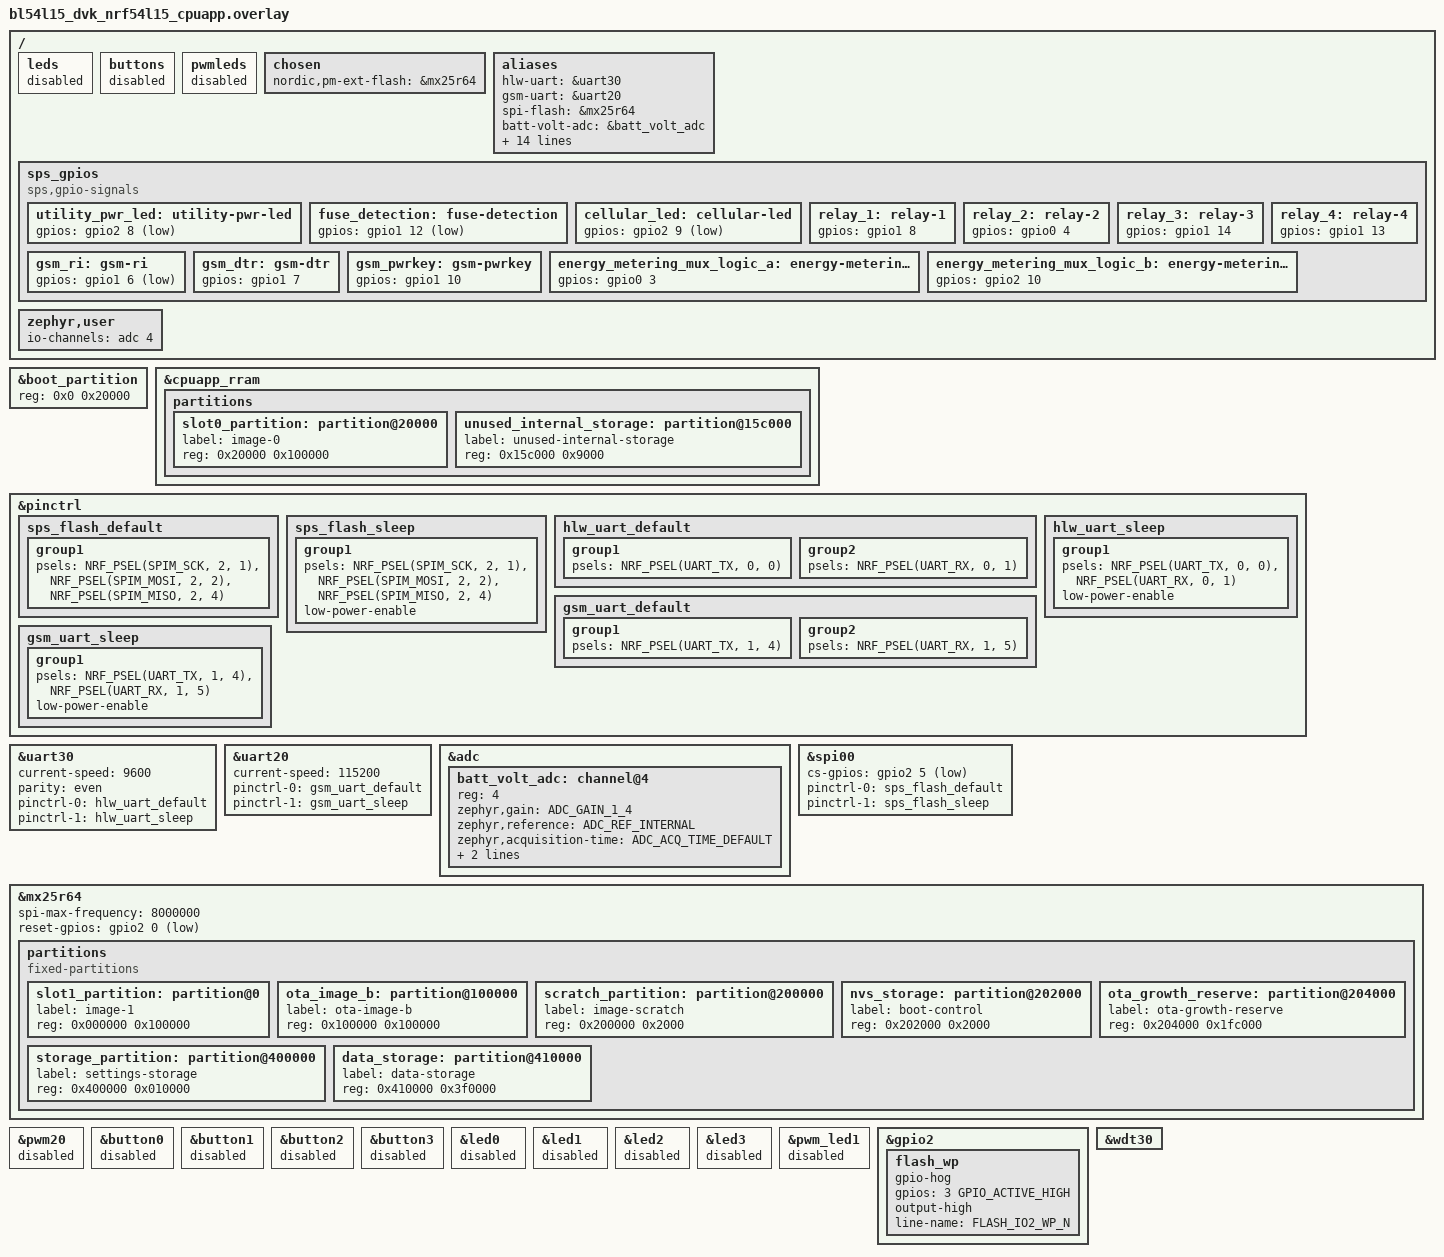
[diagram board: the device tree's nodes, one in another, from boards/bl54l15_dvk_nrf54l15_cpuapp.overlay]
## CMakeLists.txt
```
# SPDX-License-Identifier: Apache-2.0

cmake_minimum_required(VERSION 3.20.0)

find_package(Zephyr REQUIRED HINTS $ENV{ZEPHYR_BASE})
project(smart_power_socket)

target_sources(app PRIVATE
	src/main.cpp
	src/alerts.cpp
	src/sms_commands.cpp
	src/device_status.cpp
	src/app_config.cpp
	src/hardware/gpio_con.cpp
	src/hardware/uart_con.cpp
	src/hardware/adc_con.cpp
	src/sensors/hlw811x.cpp
	src/sensors/externalLibs/hlw811x/hlw811x.c
	src/cellular/at_engine.cpp
	src/cellular/sim7080.cpp
)

target_include_directories(app PRIVATE
	src
	src/hardware
	src/sensors
	src/sensors/externalLibs/hlw811x
	src/cellular/
)

if(CONFIG_BOOTLOADER_MCUBOOT)
  if(NOT CONFIG_TASK_WDT)
    message(FATAL_ERROR "The MCUboot carrier profile requires CONFIG_TASK_WDT. Include boards/bl54l15_dvk_nrf54l15_cpuapp.conf with prj.conf.")
  endif()
  if(NOT CONFIG_MBEDTLS_ENABLE_HEAP OR CONFIG_MBEDTLS_HEAP_SIZE LESS 8192)
    message(FATAL_ERROR "SPS OTA Ed25519 key import requires CONFIG_MBEDTLS_ENABLE_HEAP=y and CONFIG_MBEDTLS_HEAP_SIZE>=8192. Include the board configuration; libc heap/stack sizes do not initialize the Nordic crypto allocator.")
  endif()
  if(CONFIG_PSA_USE_CRACEN_KEY_MANAGEMENT_DRIVER AND NOT CONFIG_PSA_NEED_CRACEN_KEY_TYPE_ECC_KEY_PAIR_IMPORT)
    message(FATAL_ERROR "NCS 3.2.4 CRACEN requires CONFIG_PSA_WANT_KEY_TYPE_ECC_KEY_PAIR_IMPORT=y to import Ed25519 public keys for SPS OTA verification.")
  endif()
  target_sources(app PRIVATE
    src/ota/firmware_update.cpp
    src/ota/image_verify.cpp
    modules/sps_boot/src/boot_storage.c
    modules/sps_boot/src/watchdog_reset.c
    src/system/watchdog.cpp
  )
  if(NOT CONFIG_MCUBOOT_BOOTLOADER_SIGNATURE_TYPE_ED25519 OR CONFIG_MCUBOOT_BOOTLOADER_SIGNATURE_TYPE_PURE)
    message(FATAL_ERROR "SPS OTA requires MCUboot SHA-512/Ed25519 hash signing")
  endif()
  set(ota_key_header ${CMAKE_CURRENT_BINARY_DIR}/ota_generated/ota_public_key.hpp)
  set(ota_key_metadata ${CMAKE_CURRENT_BINARY_DIR}/ota_generated/trusted_keys.json)
  set(ota_public_keys
    ${CMAKE_CURRENT_SOURCE_DIR}/keys/ota/public/primary-ed25519.pem
    ${CMAKE_CURRENT_SOURCE_DIR}/keys/ota/public/recovery-ed25519.pem)
  add_custom_command(OUTPUT ${ota_key_header} ${ota_key_metadata}
    COMMAND ${PYTHON_EXECUTABLE} ${CMAKE_CURRENT_SOURCE_DIR}/tools/export_ota_key.py
      --key ${CMAKE_CURRENT_SOURCE_DIR}/keys/ota/public/primary-ed25519.pem
      --key ${CMAKE_CURRENT_SOURCE_DIR}/keys/ota/public/recovery-ed25519.pem
      --output ${ota_key_header} --metadata ${ota_key_metadata}
    DEPENDS ${ota_public_keys} tools/export_ota_key.py
    VERBATIM)
  target_sources(app PRIVATE ${ota_key_header})
  target_include_directories(app PRIVATE modules/sps_boot/src ${CMAKE_CURRENT_BINARY_DIR}/ota_generated)
endif()

if(CONFIG_SPS_HTTP_OTA)
  target_sources(app PRIVATE src/ota/manifest.cpp src/ota/http_update.cpp src/cellular/sim7080_https.cpp)
endif()
```

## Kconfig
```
mainmenu "Smart Power Socket"
source "Kconfig.zephyr"

config SPS_OTA_HEALTH_CHECK
    bool "Require a healthy trial and verified backup before accepting OTA"
    depends on BOOTLOADER_MCUBOOT
    default n
    help
      Enable the timed startup health check and automatic backup provisioning.
      Disabled for now: OTA commands have no startup health prerequisite.
      The running image is still authenticated and backed up before staging
      an update. The watchdog failure streak still clears after sustained
      main-loop progress, independently of backup provisioning.

config SPS_HTTP_OTA
    bool "SMS-controlled SIM7080 HTTPS firmware updates"
    default y if BOOTLOADER_MCUBOOT
    depends on BOOTLOADER_MCUBOOT
    select JSON_LIBRARY

config SPS_OTA_BASE_URL
    string "HTTPS URL of the hosted dfu_application directory"
    depends on SPS_HTTP_OTA
    default ""
    help
      Raw HTTPS directory URL ending with /dfu_application/.
      Example: https://raw.githubusercontent.com/OWNER/REPO/main/dfu_application/
      Leave empty until the repository exists; ota commands report an error.
```

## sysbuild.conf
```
SB_CONFIG_BOOTLOADER_MCUBOOT=y
SB_CONFIG_MCUBOOT_MODE_SWAP_SCRATCH=y
SB_CONFIG_BOOT_SIGNATURE_TYPE_ED25519=y
SB_CONFIG_MCUBOOT_SIGNATURE_USING_KMU=n
SB_CONFIG_BOOT_SIGNATURE_TYPE_PURE=n

# Project-relative path: identical checkout layout on both signing machines.
SB_CONFIG_BOOT_SIGNATURE_KEY_FILE="keys/ota/private/primary-ed25519.pem"
```

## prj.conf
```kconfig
# CPP config
CONFIG_MAIN_STACK_SIZE=16384
# Extra headroom for UART/GPIO interrupts and deferred log formatting.
CONFIG_ISR_STACK_SIZE=4096
CONFIG_LOG_PROCESS_THREAD_STACK_SIZE=2048
CONFIG_HW_STACK_PROTECTION=y
# Diagnose actual stack usage during meter polling, flash saves and SMS traffic.
CONFIG_THREAD_NAME=y
CONFIG_THREAD_ANALYZER=y
CONFIG_SCHED_THREAD_USAGE_ALL=y
CONFIG_THREAD_ANALYZER_USE_LOG=y
CONFIG_THREAD_ANALYZER_AUTO=y
CONFIG_THREAD_ANALYZER_AUTO_INTERVAL=60
CONFIG_THREAD_ANALYZER_AUTO_STACK_SIZE=2048
CONFIG_CPP=y
CONFIG_REQUIRES_FULL_LIBCPP=y
CONFIG_NEWLIB_LIBC=y
CONFIG_STD_CPP20=y


# hardware config
CONFIG_GPIO=y
CONFIG_HWINFO=y
CONFIG_SERIAL=y
CONFIG_UART_USE_RUNTIME_CONFIGURE=y
# CONFIG_UART_ASYNC_API=y
# CONFIG_UART_20_ASYNC=y
# CONFIG_UART_30_ASYNC=y
CONFIG_UART_INTERRUPT_DRIVEN=y
CONFIG_UART_20_INTERRUPT_DRIVEN=y
CONFIG_UART_30_INTERRUPT_DRIVEN=y
CONFIG_UART_30_NRF_PARITY_BIT=y
CONFIG_ADC=y
# External MX25R6435F on hardware SPIM00.
CONFIG_SPI=y
CONFIG_SPI_NOR=y
CONFIG_GPIO_HOGS=y
CONFIG_FLASH=y
CONFIG_FLASH_MAP=y
CONFIG_FLASH_PAGE_LAYOUT=y
CONFIG_NVS=y
CONFIG_SETTINGS=y
CONFIG_SETTINGS_NVS=y

# Logging
CONFIG_UART_CONSOLE=n
CONFIG_LOG_BACKEND_UART=n
CONFIG_SHELL=n
CONFIG_USE_SEGGER_RTT=y
CONFIG_RTT_CONSOLE=y
CONFIG_LOG=y
# Keep command-stage/reset diagnostics during bursts of normal meter logs.
CONFIG_LOG_BUFFER_SIZE=4096
#CONFIG_LOG_DEFAULT_LEVEL=4
CONFIG_LOG_BACKEND_RTT=y
```

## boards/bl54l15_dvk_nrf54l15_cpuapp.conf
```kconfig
# 4 KiB NOR erase sectors; NVS cannot use the driver's default 64 KiB pages.
CONFIG_SPI_NOR_FLASH_LAYOUT_PAGE_SIZE=4096
CONFIG_FLASH_JESD216_API=y
CONFIG_SETTINGS_NVS_SECTOR_COUNT=16
CONFIG_PM_PARTITION_REGION_SETTINGS_STORAGE_EXTERNAL=y
CONFIG_PM_PARTITION_SIZE_SETTINGS_STORAGE=0x10000

# MCUboot image management and a separate boot-policy NVS journal.
CONFIG_IMG_MANAGER=y
CONFIG_WATCHDOG=y
CONFIG_FLASH_AREA_CHECK_INTEGRITY=y
CONFIG_STREAM_FLASH=y
# Temporarily bypass the startup health/backup prerequisite for OTA commands.
CONFIG_SPS_OTA_HEALTH_CHECK=n
CONFIG_FLASH_AREA_CHECK_INTEGRITY_PSA=y
CONFIG_NRF_SECURITY=y
# Nordic's PSA key import uses the mbed TLS allocator, not the libc heap.
# Without its initialized heap, Ed25519 public-key import fails with PSA -141.
CONFIG_MBEDTLS_ENABLE_HEAP=y
CONFIG_MBEDTLS_HEAP_SIZE=8192
CONFIG_REBOOT=y

# Zephyr supervises the main task; its timer feeds the inherited WDT30.
CONFIG_TASK_WDT=y
CONFIG_TASK_WDT_CHANNELS=2
CONFIG_TASK_WDT_HW_FALLBACK=y
CONFIG_TASK_WDT_MIN_TIMEOUT=10000
CONFIG_TASK_WDT_HW_FALLBACK_DELAY=10000

# Authenticate staged OTA images before reboot, using the MCUboot public key.
CONFIG_PSA_WANT_ALG_SHA_512=y
CONFIG_PSA_WANT_ALG_PURE_EDDSA=y
CONFIG_PSA_WANT_ECC_TWISTED_EDWARDS_255=y
CONFIG_PSA_WANT_KEY_TYPE_ECC_PUBLIC_KEY=y
# NCS 3.2.4 CRACEN gates import_ecc_public_key() on the ECC import feature.
CONFIG_PSA_WANT_KEY_TYPE_ECC_KEY_PAIR_IMPORT=y

# Public release directory: manifest.json and its named signed application.
CONFIG_SPS_HTTP_OTA=y
CONFIG_SPS_OTA_BASE_URL="https://raw.githubusercontent.com/haseebzaib/SPS_OTA_UPDATE/main/dfu_application/"
```

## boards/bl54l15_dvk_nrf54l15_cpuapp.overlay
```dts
/* Custom SPS carrier with Ezurio BL54L15 (453-00001R). */
#include <zephyr/dt-bindings/gpio/gpio.h>
#include <zephyr/dt-bindings/pinctrl/nrf-pinctrl.h>
#include <zephyr/dt-bindings/adc/adc.h>
#include <zephyr/dt-bindings/adc/nrf-saadc.h>

/* Move the settings label to NOR; leave the previous RRAM area unused. */
/delete-node/ &storage_partition;
/delete-node/ &slot1_partition;
/delete-node/ &slot0_partition;
&boot_partition { reg = <0x0 0x20000>; };
&cpuapp_rram {
	partitions {
		slot0_partition: partition@20000 {
			label = "image-0";
			reg = <0x20000 0x100000>;
		};
		unused_internal_storage: partition@15c000 {
			label = "unused-internal-storage";
			reg = <0x15c000 0x9000>;
		};
	};
};

/ {
	/* The DVK peripherals are not fitted on this custom carrier. */
	leds { status = "disabled"; };
	buttons { status = "disabled"; };
	pwmleds { status = "disabled"; };

	chosen {
		nordic,pm-ext-flash = &mx25r64;
		/delete-property/ zephyr,console;
		/delete-property/ zephyr,shell-uart;
		/delete-property/ zephyr,uart-mcumgr;
		/delete-property/ zephyr,bt-mon-uart;
		/delete-property/ zephyr,bt-c2h-uart;
	};

	aliases {
		hlw-uart = &uart30;
		gsm-uart = &uart20;
		spi-flash = &mx25r64;

		batt-volt-adc = &batt_volt_adc;

		utility-pwr-led = &utility_pwr_led;
		fuse-detection = &fuse_detection;
		cellular-led = &cellular_led;

		relay1 = &relay_1;
		relay2 = &relay_2;
		relay3 = &relay_3;
		relay4 = &relay_4;

		gsm-ri = &gsm_ri;
		gsm-dtr = &gsm_dtr;
		gsm-pwrkey = &gsm_pwrkey;

		energy-metering-mux-a = &energy_metering_mux_logic_a;
		energy-metering-mux-b = &energy_metering_mux_logic_b;
	};

	sps_gpios {
		compatible = "sps,gpio-signals";
		utility_pwr_led: utility-pwr-led {
			gpios = <&gpio2 8 GPIO_ACTIVE_LOW>;
		};

		/* External R78 pulls high; the optocoupler pulls low with input AC. */
		fuse_detection: fuse-detection {
			gpios = <&gpio1 12 GPIO_ACTIVE_LOW>;
		};

		cellular_led: cellular-led {
			gpios = <&gpio2 9 GPIO_ACTIVE_LOW>;
		};

		relay_1: relay-1 {
			gpios = <&gpio1 8 GPIO_ACTIVE_HIGH>;
		};

		relay_2: relay-2 {
			gpios = <&gpio0 4 GPIO_ACTIVE_HIGH>;
		};

		relay_3: relay-3 {
			gpios = <&gpio1 14 GPIO_ACTIVE_HIGH>;
		};

		relay_4: relay-4 {
			gpios = <&gpio1 13 GPIO_ACTIVE_HIGH>;
		};

		/* P1.09 is reserved for future debug TX and remains unconfigured. */
		gsm_ri: gsm-ri {
			gpios = <&gpio1 6 (GPIO_PULL_UP | GPIO_ACTIVE_LOW)>;
		};

		gsm_dtr: gsm-dtr {
			gpios = <&gpio1 7 GPIO_ACTIVE_HIGH>;
		};

		gsm_pwrkey: gsm-pwrkey {
			gpios = <&gpio1 10 GPIO_ACTIVE_HIGH>;
		};

		energy_metering_mux_logic_a: energy-metering-mux-logic-a {
			gpios = <&gpio0 3 GPIO_ACTIVE_HIGH>;
		};

		energy_metering_mux_logic_b: energy-metering-mux-logic-b {
			gpios = <&gpio2 10 GPIO_ACTIVE_HIGH>;
		};
	};

	zephyr,user {
		io-channels = <&adc 4>;
	};
};

&pinctrl {
	/* FLASH_CLK P2.01, FLASH_IO0 P2.02, FLASH_IO1 P2.04. */
	sps_flash_default: sps_flash_default {
		group1 {
			psels = <NRF_PSEL(SPIM_SCK, 2, 1)>,
				<NRF_PSEL(SPIM_MOSI, 2, 2)>,
				<NRF_PSEL(SPIM_MISO, 2, 4)>;
		};
	};

	sps_flash_sleep: sps_flash_sleep {
		group1 {
			psels = <NRF_PSEL(SPIM_SCK, 2, 1)>,
				<NRF_PSEL(SPIM_MOSI, 2, 2)>,
				<NRF_PSEL(SPIM_MISO, 2, 4)>;
			low-power-enable;
		};
	};

	hlw_uart_default: hlw_uart_default {
		group1 {
			psels = <NRF_PSEL(UART_TX, 0, 0)>;
		};

		group2 {
			psels = <NRF_PSEL(UART_RX, 0, 1)>;
		};
	};

	hlw_uart_sleep: hlw_uart_sleep {
		group1 {
			psels = <NRF_PSEL(UART_TX, 0, 0)>,
				<NRF_PSEL(UART_RX, 0, 1)>;
			low-power-enable;
		};
	};

	gsm_uart_default: gsm_uart_default {
		group1 {
			psels = <NRF_PSEL(UART_TX, 1, 4)>;
		};

		group2 {
			psels = <NRF_PSEL(UART_RX, 1, 5)>;
		};
	};

	gsm_uart_sleep: gsm_uart_sleep {
		group1 {
			psels = <NRF_PSEL(UART_TX, 1, 4)>,
				<NRF_PSEL(UART_RX, 1, 5)>;
			low-power-enable;
		};
	};
};

&uart30 {
	status = "okay";
	current-speed = <9600>;
	parity = "even";
	pinctrl-0 = <&hlw_uart_default>;
	pinctrl-1 = <&hlw_uart_sleep>;
	pinctrl-names = "default", "sleep";
};

&uart20 {
	status = "okay";
	current-speed = <115200>;
	pinctrl-0 = <&gsm_uart_default>;
	pinctrl-1 = <&gsm_uart_sleep>;
	pinctrl-names = "default", "sleep";
};

&adc {
	status = "okay";
	#address-cells = <1>;
	#size-cells = <0>;

	batt_volt_adc: channel@4 {
		reg = <4>;
		zephyr,gain = "ADC_GAIN_1_4";
		zephyr,reference = "ADC_REF_INTERNAL";
		zephyr,acquisition-time = <ADC_ACQ_TIME_DEFAULT>;
		zephyr,input-positive = <NRF_SAADC_AIN4>;
		zephyr,resolution = <12>;
	};
};

/* Hardware SPIM00 matches the confirmed flash wiring. */
&spi00 {
	status = "okay";
	cs-gpios = <&gpio2 5 GPIO_ACTIVE_LOW>;
	pinctrl-0 = <&sps_flash_default>;
	pinctrl-1 = <&sps_flash_sleep>;
	pinctrl-names = "default", "sleep";
};

&mx25r64 {
	status = "okay";
	spi-max-frequency = <8000000>;
	/* FLASH_IO3 / RESET# is P2.00 in single-lane SPI mode. */
	reset-gpios = <&gpio2 0 GPIO_ACTIVE_LOW>;
	partitions {
		compatible = "fixed-partitions";
		#address-cells = <1>;
		#size-cells = <1>;
		slot1_partition: partition@0 {
			label = "image-1";
			reg = <0x000000 0x100000>;
		};
		ota_image_b: partition@100000 {
			label = "ota-image-b";
			reg = <0x100000 0x100000>;
		};
		scratch_partition: partition@200000 {
			label = "image-scratch";
			reg = <0x200000 0x2000>;
		};
		nvs_storage: partition@202000 {
			label = "boot-control";
			reg = <0x202000 0x2000>;
		};
		/* Keep persisted settings in place while reserving future growth. */
		ota_growth_reserve: partition@204000 {
			label = "ota-growth-reserve";
			reg = <0x204000 0x1fc000>;
		};
		storage_partition: partition@400000 {
			label = "settings-storage";
			reg = <0x400000 0x010000>;
		};
		data_storage: partition@410000 {
			label = "data-storage";
			reg = <0x410000 0x3f0000>;
		};
	};
};

/* PWM20 would otherwise claim P1.10 (GSM_PWRKEY). */
&pwm20 {
	status = "disabled";
};

&button0 { status = "disabled"; };
&button1 { status = "disabled"; };
&button2 { status = "disabled"; };
&button3 { status = "disabled"; };
&led0 { status = "disabled"; };
&led1 { status = "disabled"; };
&led2 { status = "disabled"; };
&led3 { status = "disabled"; };
&pwm_led1 { status = "disabled"; };

/* Keep FLASH_IO2 / WP# high in single-lane SPI mode. */
&gpio2 {
	flash_wp {
		gpio-hog;
		gpios = <3 GPIO_ACTIVE_HIGH>;
		output-high;
		line-name = "FLASH_IO2_WP_N";
	};
};

/* Shared 20-second hardware watchdog, handed from MCUboot to the application. */
&wdt30 { status = "okay"; };
```

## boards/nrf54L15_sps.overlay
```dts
#include <zephyr/dt-bindings/gpio/gpio.h>
#include <zephyr/dt-bindings/pinctrl/nrf-pinctrl.h>
#include <zephyr/dt-bindings/adc/adc.h>
#include <zephyr/dt-bindings/adc/nrf-saadc.h>

/ {
	chosen {
		/delete-property/ zephyr,console;
		/delete-property/ zephyr,shell-uart;
		/delete-property/ zephyr,uart-mcumgr;
		/delete-property/ zephyr,bt-mon-uart;
		/delete-property/ zephyr,bt-c2h-uart;
	};

	aliases {
		hlw-uart = &uart30;
		gsm-uart = &uart20;

		batt-volt-adc = &batt_volt_adc;

		utility-pwr-led = &utility_pwr_led;
		cellular-led = &cellular_led;

		relay1 = &relay_1;
		relay2 = &relay_2;
		relay3 = &relay_3;
		relay4 = &relay_4;

		gsm-ri = &gsm_ri;
		gsm-dtr = &gsm_dtr;
		gsm-pwrkey = &gsm_pwrkey;

		energy-metering-mux-a = &energy_metering_mux_logic_a;
		energy-metering-mux-b = &energy_metering_mux_logic_b;
	};

	sps_gpios {
		compatible = "sps,gpio-signals";
		utility_pwr_led: utility-pwr-led {
			gpios = <&gpio2 4 GPIO_ACTIVE_LOW>;
		};

		cellular_led: cellular-led {
			gpios = <&gpio2 5 GPIO_ACTIVE_LOW>;
		};

		relay_1: relay-1 {
			gpios = <&gpio2 0 GPIO_ACTIVE_HIGH>;
		};

		relay_2: relay-2 {
			gpios = <&gpio2 1 GPIO_ACTIVE_HIGH>;
		};

		relay_3: relay-3 {
			gpios = <&gpio2 2 GPIO_ACTIVE_HIGH>;
		};

		relay_4: relay-4 {
			gpios = <&gpio2 3 GPIO_ACTIVE_HIGH>;
		};

		gsm_ri: gsm-ri {
			gpios = <&gpio1 6 (GPIO_PULL_UP | GPIO_ACTIVE_LOW)>;
		};

		gsm_dtr: gsm-dtr {
			gpios = <&gpio1 7 GPIO_ACTIVE_HIGH>;
		};

		gsm_pwrkey: gsm-pwrkey {
			gpios = <&gpio1 8 GPIO_ACTIVE_HIGH>;
		};

		energy_metering_mux_logic_a: energy-metering-mux-logic-a {
			gpios = <&gpio0 3 GPIO_ACTIVE_HIGH>;
		};

		energy_metering_mux_logic_b: energy-metering-mux-logic-b {
			gpios = <&gpio0 4 GPIO_ACTIVE_HIGH>;
		};
	};

	zephyr,user {
		io-channels = <&adc 4>;
	};
};

&pinctrl {
	hlw_uart_default: hlw_uart_default {
		group1 {
			psels = <NRF_PSEL(UART_TX, 0, 0)>;
		};

		group2 {
			psels = <NRF_PSEL(UART_RX, 0, 1)>;
		};
	};

	hlw_uart_sleep: hlw_uart_sleep {
		group1 {
			psels = <NRF_PSEL(UART_TX, 0, 0)>,
				<NRF_PSEL(UART_RX, 0, 1)>;
			low-power-enable;
		};
	};

	gsm_uart_default: gsm_uart_default {
		group1 {
			psels = <NRF_PSEL(UART_TX, 1, 4)>;
		};

		group2 {
			psels = <NRF_PSEL(UART_RX, 1, 5)>;
		};
	};

	gsm_uart_sleep: gsm_uart_sleep {
		group1 {
			psels = <NRF_PSEL(UART_TX, 1, 4)>,
				<NRF_PSEL(UART_RX, 1, 5)>;
			low-power-enable;
		};
	};
};

&uart30 {
	status = "okay";
	current-speed = <9600>;
	parity = "even";
	pinctrl-0 = <&hlw_uart_default>;
	pinctrl-1 = <&hlw_uart_sleep>;
	pinctrl-names = "default", "sleep";
};

&uart20 {
	status = "okay";
	current-speed = <115200>;
	pinctrl-0 = <&gsm_uart_default>;
	pinctrl-1 = <&gsm_uart_sleep>;
	pinctrl-names = "default", "sleep";
};

&adc {
	status = "okay";
	#address-cells = <1>;
	#size-cells = <0>;

	batt_volt_adc: channel@4 {
		reg = <4>;
		zephyr,gain = "ADC_GAIN_1_4";
		zephyr,reference = "ADC_REF_INTERNAL";
		zephyr,acquisition-time = <ADC_ACQ_TIME_DEFAULT>;
		zephyr,input-positive = <NRF_SAADC_AIN4>;
		zephyr,resolution = <12>;
	};
};

/*
 * The DK external flash uses pins that this custom board uses for
 * relays/LEDs, so disable the DK flash SPI instance.
 */
&spi00 {
	status = "disabled";
};

&mx25r64 {
	status = "disabled";
};

/* DK buttons conflict with GSM_PWRKEY and mux logic B. */
&button2 {
	status = "disabled";
};

&button3 {
	status = "disabled";
};
```

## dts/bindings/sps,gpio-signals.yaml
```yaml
description: Smart power socket GPIO signal group

compatible: "sps,gpio-signals"

child-binding:
  description: GPIO signal
  properties:
    gpios:
      type: phandle-array
      required: true

    label:
      type: string
```

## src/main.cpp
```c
/*
 * Copyright (c) 2023, Meta
 *
 * SPDX-License-Identifier: Apache-2.0
 */

#include <array>
#include <iostream>
#include <span>
#include <string_view>
#include <zephyr/kernel.h>
#include <zephyr/sys/printk.h>
#include <zephyr/sys/ring_buffer.h>
#include <zephyr/drivers/uart.h>
#include <zephyr/drivers/hwinfo.h>
#include <zephyr/logging/log.h>

#include "hardware/gpio_con.hpp"
#include "hardware/uart_con.hpp"
#include "hardware/adc_con.hpp"
#include "sensors/hlw811x.hpp"
#include "cellular/at_engine.hpp"
#include "cellular/sim7080.hpp"
#include "sms_commands.hpp"
#include "alerts.hpp"
#include "app_config.hpp"
#include "system/watchdog.hpp"
#if defined(CONFIG_BOOTLOADER_MCUBOOT)
#include "ota/firmware_update.hpp"
#if defined(CONFIG_SPS_HTTP_OTA)
#include "ota/http_update.hpp"
#endif
#include "sps_boot.h"
#endif

LOG_MODULE_REGISTER(mainCpp, LOG_LEVEL_INF);

hardware::gpioCon utilityPwrLed(GPIO_DT_SPEC_GET(DT_ALIAS(utility_pwr_led), gpios), GPIO_OUTPUT_HIGH);
#if DT_NODE_EXISTS(DT_ALIAS(fuse_detection))
hardware::gpioCon fuseDetection(GPIO_DT_SPEC_GET(DT_ALIAS(fuse_detection), gpios), GPIO_INPUT);
bool fuseDetectionReady = false;
namespace
{
	const gpio_dt_spec fuseDetectionGpio = GPIO_DT_SPEC_GET(DT_ALIAS(fuse_detection), gpios);
	gpio_callback fuseDetectionCallback{};
	k_spinlock fusePulseLock{};
	std::array<uint32_t, 8> fusePeriodsUs{};
	uint32_t fusePeriodSumUs = 0;
	uint32_t fusePreviousCycle = 0;
	uint32_t fuseEdgeCount = 0;
	uint32_t fuseRejectedIntervals = 0;
	uint32_t fuseLastPeriodUs = 0;
	int64_t fuseLastEdgeMs = -1;
	size_t fusePeriodCount = 0;
	size_t fusePeriodIndex = 0;
	bool fuseFrequencyReady = false;

	void fuse_detection_edge(const device *, gpio_callback *, gpio_port_pins_t)
	{
		const uint32_t cycle = k_cycle_get_32();
		const int64_t nowMs = k_uptime_get();
		const auto key = k_spin_lock(&fusePulseLock);
		const uint32_t periodUs = static_cast<uint32_t>(
			k_cyc_to_us_floor64(static_cast<uint32_t>(cycle - fusePreviousCycle)));
		++fuseEdgeCount;
		fuseLastPeriodUs = fuseLastEdgeMs >= 0 ? periodUs : 0;
		// Two active pulses per mains cycle. Reject glitches and missing cycles;
		// 6-15 ms covers the expected 50/60 Hz half-cycle interval.
		if (fuseLastEdgeMs >= 0 && nowMs - fuseLastEdgeMs <= 40 &&
			periodUs >= 6000 && periodUs <= 15000)
		{
			if (fusePeriodCount == fusePeriodsUs.size())
				fusePeriodSumUs -= fusePeriodsUs[fusePeriodIndex];
			else
				++fusePeriodCount;
			fusePeriodsUs[fusePeriodIndex] = periodUs;
			fusePeriodSumUs += periodUs;
			fusePeriodIndex = (fusePeriodIndex + 1) % fusePeriodsUs.size();
		}
		else
		{
			if (fuseLastEdgeMs >= 0) ++fuseRejectedIntervals;
			fusePeriodCount = 0;
			fusePeriodIndex = 0;
			fusePeriodSumUs = 0;
		}
		fusePreviousCycle = cycle;
		fuseLastEdgeMs = nowMs;
		k_spin_unlock(&fusePulseLock, key);
	}

	void log_fuse_detection(bool acPresent)
	{
		const int64_t nowMs = k_uptime_get();
		const auto key = k_spin_lock(&fusePulseLock);
		const bool frequencyValid = fuseFrequencyReady && acPresent &&
			fuseLastEdgeMs >= 0 && nowMs - fuseLastEdgeMs <= 40 && fusePeriodCount >= 3;
		const uint32_t frequencyCentiHz = frequencyValid ?
			static_cast<uint32_t>(50000000ULL * fusePeriodCount / fusePeriodSumUs) : 0;
		const uint32_t edges = fuseEdgeCount;
		const uint32_t rejected = fuseRejectedIntervals;
		const uint32_t lastPeriodUs = fuseLastPeriodUs;
		const unsigned validPeriods = static_cast<unsigned>(fusePeriodCount);
		const int64_t lastEdgeAgeMs = fuseLastEdgeMs >= 0 ? nowMs - fuseLastEdgeMs : -1;
		k_spin_unlock(&fusePulseLock, key);

		static int64_t nextLogMs = 0;
		static bool lastPresent = false;
		static bool lastFrequencyValid = false;
		if (nowMs < nextLogMs && acPresent == lastPresent &&
			frequencyValid == lastFrequencyValid) return;
		if (!acPresent)
			LOG_INF("fuse_detection: AC unavailable, freq unavailable");
		else if (frequencyValid)
			LOG_INF("fuse_detection: AC available, freq ~%u.%02u Hz (pulse %u.%02u Hz)",
					frequencyCentiHz / 100U, frequencyCentiHz % 100U,
					frequencyCentiHz * 2U / 100U, frequencyCentiHz * 2U % 100U);
		else
		{
			const char *reason = !fuseFrequencyReady ? "pulse timing disabled" :
				edges == 0 ? "no active edges observed" :
				lastEdgeAgeMs > 40 ? "no recent active edges" : "insufficient valid intervals";
			LOG_INF("fuse_detection: AC available, freq unavailable (%s)", reason);
			LOG_INF("fuse_detection: raw=%d edges=%u valid_intervals=%u rejected=%u last_period_us=%u edge_age_ms=%lld",
					gpio_pin_get_raw(fuseDetectionGpio.port, fuseDetectionGpio.pin),
					edges, validPeriods, rejected, lastPeriodUs,
					static_cast<long long>(lastEdgeAgeMs));
		}
		lastPresent = acPresent;
		lastFrequencyValid = frequencyValid;
		nextLogMs = nowMs + 10000;
	}
}
#endif

bool input_ac_present()
{
#if DT_NODE_EXISTS(DT_ALIAS(fuse_detection))
	if (!fuseDetectionReady)
	{
		return false;
	}

	// AC optocoupler output pulses low. Observe at least two 50 Hz cycles
	// rather than treating a high sample near a zero crossing as no AC.
	const int64_t deadlineMs = k_uptime_get() + 40;
	do
	{
		const int value = fuseDetection.get();
		if (value < 0)
		{
			LOG_ERR("Fuse detection GPIO read failed: %d", value);
			return false;
		}
		if (value == 1) // GPIO_ACTIVE_LOW: a low level means input AC present.
		{
			log_fuse_detection(true);
			return true;
		}
		k_msleep(1);
	} while (k_uptime_get() < deadlineMs);
	log_fuse_detection(false);
#endif
	return false;
}

hardware::gpioCon cellularLed(GPIO_DT_SPEC_GET(DT_ALIAS(cellular_led), gpios), GPIO_OUTPUT_HIGH);
// State reporting/persistence reads the pin; keep the input buffer connected
// while driving each relay output. Nordic GPIO disconnects it for output-only.
hardware::gpioCon relay1(GPIO_DT_SPEC_GET(DT_ALIAS(relay1), gpios), GPIO_OUTPUT_INACTIVE | GPIO_INPUT);
hardware::gpioCon relay2(GPIO_DT_SPEC_GET(DT_ALIAS(relay2), gpios), GPIO_OUTPUT_INACTIVE | GPIO_INPUT);
hardware::gpioCon relay3(GPIO_DT_SPEC_GET(DT_ALIAS(relay3), gpios), GPIO_OUTPUT_INACTIVE | GPIO_INPUT);
hardware::gpioCon relay4(GPIO_DT_SPEC_GET(DT_ALIAS(relay4), gpios), GPIO_OUTPUT_INACTIVE | GPIO_INPUT);

hardware::adcCon batteryAdc(HARDWARE_ADC_CHANNEL_DT_SPEC_GET(DT_ALIAS(batt_volt_adc)), 110000, 110000);

cellular::sim7080 modemSim7080(DEVICE_DT_GET(DT_ALIAS(gsm_uart)),
							   GPIO_DT_SPEC_GET(DT_ALIAS(gsm_pwrkey), gpios), GPIO_OUTPUT_INACTIVE,
							   GPIO_DT_SPEC_GET(DT_ALIAS(gsm_dtr), gpios), GPIO_OUTPUT_INACTIVE);

sensors::hlw811x energyMeters(
	DEVICE_DT_GET(DT_ALIAS(hlw_uart)),
	GPIO_DT_SPEC_GET(DT_ALIAS(energy_metering_mux_a), gpios),
	GPIO_DT_SPEC_GET(DT_ALIAS(energy_metering_mux_b), gpios),
	4);

const hlw811x_pga baselinePga = {
	.A = HLW811X_PGA_GAIN_16,
	.B = HLW811X_PGA_GAIN_1,
	.U = HLW811X_PGA_GAIN_1,
};

std::array<int, 4> energyMeterErr;
std::array<int64_t, 4> nextEnergyMeterRetryMs;

std::array<sensors::hlw811x::measurements, 4> acMeasurements;
std::array<bool, device_status::outletCount> monitoredLoadConnected{};
std::array<bool, device_status::outletCount> monitoredLoadStateValid{};
std::array<uint32_t, device_status::outletCount> relayChangeSequence{};
std::array<hardware::gpioCon *, device_status::outletCount> outletRelays = {{
	&relay1,
	&relay2,
	&relay3,
	&relay4,
}};

std::string_view alert_number = "1234567890";
uint32_t heartBeatDaysMilli = 0;
uint32_t batteryMillivolts = 0;
alerts::utilityPowerMonitor utilityPowerAlerts;
alerts::devicePowerMonitor devicePowerAlerts;
alerts::frequencyMonitor frequencyAlerts;
alerts::powerFactorMonitor powerFactorAlerts;

constexpr int64_t energyMeterRetryIntervalMs = 30000;
constexpr int64_t modemInitRetryIntervalMs = 30000;
constexpr int64_t startupStatusRetryIntervalMs = 5LL * 60LL * 1000LL;

bool sms_network_ready(const cellular::sim7080::modemInformation &modemInfo)
{
	return modemInfo.networkRegistration == 1 || modemInfo.networkRegistration == 5;
}

int main(void)
{
	const int64_t bootTimeMs = k_uptime_get();
	uint32_t resetCause = 0;
	int resetRet = hwinfo_get_reset_cause(&resetCause);
#if defined(CONFIG_BOOTLOADER_MCUBOOT)
    sps_boot_state bootState{};
    if (sps_boot_state_load(&bootState) == 0)
    {
        resetCause = bootState.reset_cause;
        resetRet = 0;
    }
#endif
	if (resetRet == 0)
	{
		LOG_INF("Boot reset cause: 0x%08x pin=%u software=%u watchdog=%u lockup=%u debug=%u",
				resetCause, !!(resetCause & RESET_PIN), !!(resetCause & RESET_SOFTWARE),
				!!(resetCause & RESET_WATCHDOG), !!(resetCause & RESET_CPU_LOCKUP),
				!!(resetCause & RESET_DEBUG));
		if (resetCause == 0)
			LOG_INF("No classified reset cause; power-on/supply interruption remains possible");
		const int clearRet = hwinfo_clear_reset_cause();
		if (clearRet != 0) LOG_WRN("Reset cause clear failed: %d", clearRet);
	}
	else
		LOG_WRN("Reset cause unavailable: %d", resetRet);
#if defined(CONFIG_BOOTLOADER_MCUBOOT)
	const int firmwareUpdateRet = firmware_update::init();
	LOG_INF("OTA init ret: %d", firmwareUpdateRet);
#endif
	const int appConfigRet = app_config::init();
	LOG_INF("App config init ret: %d", appConfigRet);
	heartBeatDaysMilli = app_config::heartbeat_days_milli();
	int64_t nextHeartbeatMs = device_status::next_heartbeat_uptime_ms(bootTimeMs,
													 heartBeatDaysMilli,
													 k_uptime_get());

	utilityPwrLed.init();
#if DT_NODE_EXISTS(DT_ALIAS(fuse_detection))
	const int fuseDetectionRet = fuseDetection.init();
	fuseDetectionReady = fuseDetectionRet == 0;
	if (!fuseDetectionReady)
	{
		LOG_ERR("Fuse detection GPIO init failed: %d", fuseDetectionRet);
	}
	else
	{
		gpio_init_callback(&fuseDetectionCallback, fuse_detection_edge,
						   BIT(fuseDetectionGpio.pin));
		int ret = gpio_add_callback(fuseDetectionGpio.port, &fuseDetectionCallback);
		if (ret == 0)
			ret = gpio_pin_interrupt_configure_dt(&fuseDetectionGpio, GPIO_INT_EDGE_TO_ACTIVE);
		fuseFrequencyReady = ret == 0;
		if (!fuseFrequencyReady)
			LOG_WRN("fuse_detection: pulse timing init failed: %d; AC presence still sampled", ret);
		else
			LOG_INF("fuse_detection: pulse timing enabled on P1.12; two pulses per AC cycle");
	}
#endif
	cellularLed.init();
	relay1.init();
	relay2.init();
	relay3.init();
	relay4.init();
	int batteryAdcInitRet = batteryAdc.init();
	LOG_INF("Battery ADC init ret: %d", batteryAdcInitRet);

	energyMeters.init();

	for (uint8_t meter = 1; meter <= 4; ++meter)
	{
		const hlw811x_resistor_ratio ratio = app_config::ratio_for_outlet(meter - 1);
		LOG_INF("Configuring HLW811x meter %u", static_cast<unsigned int>(meter));
		energyMeterErr[meter - 1] = energyMeters.configureIndividual(meter, ratio, baselinePga);
		LOG_INF("HLW811x meter %u configure ret: %d",
				static_cast<unsigned int>(meter),
				energyMeterErr[meter - 1]);
		if (energyMeterErr[meter - 1] != 0)
		{
			nextEnergyMeterRetryMs[meter - 1] = k_uptime_get() + energyMeterRetryIntervalMs;
			LOG_WRN("HLW811x meter %u initialization failed; retry due in 30 s when main loop runs",
					static_cast<unsigned>(meter));
		}
	}

	const uint8_t startupRelayMask = app_config::relay_state_valid() ? app_config::relay_on_mask() : 0x0f;
	for (std::size_t i = 0; i < outletRelays.size(); ++i)
	{
		outletRelays[i]->set((startupRelayMask & (1U << i)) != 0U ? 0 : 1);
	}

	int modemInitRet = modemSim7080.init();
	bool modemReady = modemInitRet == 0;
	int64_t nextModemInitRetryMs =
		modemReady ? 0 : k_uptime_get() + modemInitRetryIntervalMs;
	LOG_INF("Modem init ret: %d", modemInitRet);

	cellular::sim7080::modemInformation sim7080Information{};
	bool startupStatusQueued = false;
	int64_t nextStartupStatusAttemptMs = 0;

	while (1)
	{
		app_watchdog::progress();

		for (uint8_t meter = 1; meter <= 4; ++meter)
		{
			if (energyMeterErr[meter - 1] != 0)
			{
				const int64_t nowMs = k_uptime_get();
				if (nowMs < nextEnergyMeterRetryMs[meter - 1])
				{
					continue;
				}

				const hlw811x_resistor_ratio ratio = app_config::ratio_for_outlet(meter - 1);
				LOG_INF("HLW811x meter %u configure retry begin (previous error=%d)",
						static_cast<unsigned>(meter), energyMeterErr[meter - 1]);
				energyMeterErr[meter - 1] = energyMeters.configureIndividual(meter, ratio, baselinePga);
				if (energyMeterErr[meter - 1] != 0)
				{
					nextEnergyMeterRetryMs[meter - 1] = k_uptime_get() + energyMeterRetryIntervalMs;
					LOG_WRN("HLW811x meter %u configure retry failed: %d; retry due in 30 s",
							static_cast<unsigned int>(meter),
							energyMeterErr[meter - 1]);
				}
				else
				{
					nextEnergyMeterRetryMs[meter - 1] = 0;
					LOG_INF("HLW811x meter %u configure retry succeeded; measurements resume next loop",
							static_cast<unsigned>(meter));
				}
			}
			else
			{
				int ret = energyMeters.measurement(meter, acMeasurements[meter - 1]);
				if(ret != 0)
				{   
                         acMeasurements[meter - 1] = sensors::hlw811x::measurements{};
				}
				LOG_INF("#########START#########");
				LOG_INF("HLW811x meter %d", static_cast<int>(meter));
				LOG_INF("ret= %d", ret);
				LOG_INF("mV %d", acMeasurements[meter - 1].mV);
				LOG_INF("mA %d", acMeasurements[meter - 1].mA);
				LOG_INF("mW %d", acMeasurements[meter - 1].mW);
				LOG_INF("apparentmW %d", acMeasurements[meter - 1].apparentmW);
				LOG_INF("wH %d", acMeasurements[meter - 1].wH);
				LOG_INF("hZ %d", acMeasurements[meter - 1].hZ);
				LOG_INF("pF %d", acMeasurements[meter - 1].pF);
				LOG_INF("#########END#########");
			}

			k_msleep(300);
		}

		int32_t batteryReadingMillivolts = 0;
		int batteryRet = batteryAdc.read_divider_millivolts(batteryReadingMillivolts);
		if (batteryRet == 0 && batteryReadingMillivolts >= 0)
		{
			batteryMillivolts = static_cast<uint32_t>(batteryReadingMillivolts);
		}
		else
		{
			LOG_ERR("Battery ADC read failed: %d", batteryRet);
		}
		LOG_INF("battery mV %u", static_cast<unsigned int>(batteryMillivolts));

		if (!modemReady)
		{
			const int64_t nowMs = k_uptime_get();
			if (nowMs >= nextModemInitRetryMs)
			{
				LOG_INF("Retrying modem initialization");
				modemInitRet = modemSim7080.init();
				modemReady = modemInitRet == 0;
				LOG_INF("Modem init retry ret: %d", modemInitRet);
				if (!modemReady)
				{
					nextModemInitRetryMs = k_uptime_get() + modemInitRetryIntervalMs;
				}
			}

			if (!modemReady)
			{
#if defined(CONFIG_BOOTLOADER_MCUBOOT)
				firmware_update::poll_health(appConfigRet == 0);
#endif
				k_msleep(500);
				continue;
			}
		}

		bool allowLocation = true;
#if defined(CONFIG_SPS_HTTP_OTA)
		allowLocation = !http_update::busy();
#endif
		modemSim7080.loop(sim7080Information,
			modemSim7080.can_queue_sms(sms_commands::maxCommandReplyMessages), allowLocation);

		LOG_INF("#########Sim7080Information#########");
		LOG_INF("ModelIdentification: %s", sim7080Information.modelIdentification.data());
		LOG_INF("Pin status: %s", sim7080Information.pin.data());
		LOG_INF("carrier= %s", sim7080Information.carrier.data());
		LOG_INF("imei: %s", sim7080Information.imei.data());
		LOG_INF("simId: %s", sim7080Information.simId.data());
		LOG_INF("longitude: %s", sim7080Information.longitude.data());
		LOG_INF("latitude: %s", sim7080Information.latitude.data());
		LOG_INF("networkRegistration: %d", sim7080Information.networkRegistration);
		LOG_INF("networkQuality: %d", sim7080Information.networkQuality);
		LOG_INF("dataConnected: %d", sim7080Information.dataConnected);
		LOG_INF("ipAddress: %s", sim7080Information.ipAddress.data());
		LOG_INF("smsReceived: %d", sim7080Information.smsReceived);

		sms_commands::context smsContext{
			.modem = modemSim7080,
			.modemInformation = sim7080Information,
			.energyMeters = &energyMeters,
			.meterPga = &baselinePga,
			.relays = std::span<hardware::gpioCon *, device_status::outletCount>{outletRelays},
			.measurements = std::span<const sensors::hlw811x::measurements, device_status::outletCount>{acMeasurements},
			.monitoredLoadConnected = std::span<bool, device_status::outletCount>{monitoredLoadConnected},
			.monitoredLoadStateValid = std::span<bool, device_status::outletCount>{monitoredLoadStateValid},
			.bootTimeMs = bootTimeMs,
			.heartBeatDaysMilli = heartBeatDaysMilli,
			.nextHeartbeatMs = nextHeartbeatMs,
			.batteryMillivolts = batteryMillivolts,
			.inputAcPresent = input_ac_present(),
			.relayChangeSequence = std::span<uint32_t, device_status::outletCount>{relayChangeSequence},
			.bootResetCause = resetCause,
			.bootResetCauseValid = resetRet == 0,
		};

		// Command admission reserved enough free slots for its entire reply group.
		// Execute once before background producers can use those slots.
		if (sim7080Information.smsReceived)
		{
			LOG_INF("smsNumber: %s", sim7080Information.smsNumber.data());
			LOG_INF("smsBody: %s", sim7080Information.smsBody.data());
			sms_commands::handle(smsContext);
		}
		modemSim7080.process_sms_outbox();

		if (!startupStatusQueued &&
			sms_network_ready(sim7080Information) &&
			k_uptime_get() >= nextStartupStatusAttemptMs)
		{
			startupStatusQueued = sms_commands::send_status(smsContext, alert_number, "SPS is starting");
			if (!startupStatusQueued)
			{
				nextStartupStatusAttemptMs = k_uptime_get() + startupStatusRetryIntervalMs;
				LOG_WRN("Startup status could not be queued; retrying in %lld seconds",
						static_cast<long long>(startupStatusRetryIntervalMs / 1000));
			}
		}

		// Detect events even while unregistered; the shared outbox waits for
		// network recovery before attempting submission.
		utilityPowerAlerts.process(smsContext, alert_number);
		devicePowerAlerts.process(smsContext, alert_number);
		frequencyAlerts.process(smsContext, alert_number);
		if (app_config::power_factor_alerts_enabled())
		{
			powerFactorAlerts.process(smsContext, alert_number);
		}
		else
		{
			powerFactorAlerts.reset();
		}

		if (startupStatusQueued &&
			sms_network_ready(sim7080Information) &&
			heartBeatDaysMilli > 0U &&
			nextHeartbeatMs > 0 &&
			k_uptime_get() >= nextHeartbeatMs)
		{
			if (sms_commands::send_status(smsContext, alert_number, "SPS Heartbeat"))
			{
				nextHeartbeatMs = device_status::next_heartbeat_uptime_ms(bootTimeMs,
														 heartBeatDaysMilli,
														 k_uptime_get());
			}
		}

		modemSim7080.process_sms_outbox();
#if defined(CONFIG_SPS_HTTP_OTA)
		http_update::process(modemSim7080);
#endif
		LOG_INF("#########END#########");

#if defined(CONFIG_BOOTLOADER_MCUBOOT)
		firmware_update::poll_health(appConfigRet == 0);
#endif
		k_msleep(500);
	}
	return 0;
}
```

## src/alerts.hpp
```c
#pragma once

#include <array>
#include <cstddef>
#include <cstdint>
#include <string_view>

#include "sms_commands.hpp"

namespace alerts
{

    class utilityPowerMonitor
    {
    public:
        bool process(const sms_commands::context &ctx, std::string_view recipient);

    private:
        enum class state
        {
            Unknown,
            On,
            Off,
            FuseSuspected,
        };

        static constexpr uint8_t fuseConfirmationSamples = 3;
        uint8_t fuseCandidateCount_ = 0;
        state lastState_ = state::Unknown;
    };

    class devicePowerMonitor
    {
    public:
        bool process(const sms_commands::context &ctx, std::string_view recipient);

    private:
        static constexpr std::size_t sampleWindow = 5;
        static constexpr uint8_t confirmationSamples = 3;

        enum class state
        {
            Unknown,
            Connected,
            Disconnected,
        };

        struct outletTracker
        {
            std::array<int32_t, sampleWindow> activePowerMw{};
            std::size_t nextSample = 0;
            std::size_t sampleCount = 0;
            int64_t activePowerSum = 0;
            state lastState = state::Unknown;
            state candidateState = state::Unknown;
            uint8_t candidateCount = 0;
            uint32_t observedRelaySequence = 0;
            bool settleIntentionalRelayChange = false;

            void reset();
            void add(int32_t activePower);
            bool ready() const;
            int32_t average_active_power_mw() const;
        };

        std::array<outletTracker, device_status::outletCount> outlets_{};
    };

    class frequencyMonitor
    {
    public:
        bool process(const sms_commands::context &ctx, std::string_view recipient);

    private:
        enum class state
        {
            Unknown,
            Good,
            Bad,
        };

        state lastState_ = state::Unknown;
    };

    class powerFactorMonitor
    {
    public:
        bool process(const sms_commands::context &ctx, std::string_view recipient);
        void reset();

    private:
        enum class state
        {
            Unknown,
            Good,
            Bad,
        };

        std::array<state, device_status::outletCount> lastState_{};
    };

}
```

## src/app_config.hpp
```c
#pragma once

#include <array>
#include <cstddef>
#include <cstdint>

#include "device_status.hpp"
#include "sensors/hlw811x.hpp"

namespace app_config
{

    static constexpr float defaultK1A = 3.0f;
    static constexpr float defaultK1B = 1.0f;
    static constexpr float defaultK2 = 1.064f;
    static constexpr int32_t ratioScale = 1000000;
    static constexpr uint32_t defaultOnThresholdMw = 1200;
    static constexpr uint32_t defaultOffThresholdMw = 700;
    static constexpr uint32_t startupThresholdMw = 1000;

    int init();

    hlw811x_resistor_ratio ratio_for_outlet(std::size_t outletIndex);

    int32_t k2_micro_for_outlet(std::size_t outletIndex);
    float k2_for_outlet(std::size_t outletIndex);
    int save_k2_micro(std::size_t outletIndex, int32_t k2Micro);

    bool relay_state_valid();
    uint8_t relay_on_mask();
    int save_relay_on_mask(uint8_t onMask);

    uint32_t on_threshold_mw();
    uint32_t off_threshold_mw();
    int save_on_threshold_mw(uint32_t thresholdMw);
    int save_off_threshold_mw(uint32_t thresholdMw);

    bool power_factor_alerts_enabled();
    int save_power_factor_alerts_enabled(bool enabled);

    uint32_t heartbeat_days_milli();
    int save_heartbeat_days_milli(uint32_t daysMilli);

}
```

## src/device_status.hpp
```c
#pragma once

#include <array>
#include <cstddef>
#include <cstdint>
#include <span>
#include <string_view>
#include <zephyr/app_version.h>

#include "hardware/gpio_con.hpp"
#include "sensors/hlw811x.hpp"
#include "cellular/sim7080.hpp"

namespace device_status
{

    static constexpr std::size_t outletCount = 4;
    static constexpr std::string_view firmwareVersion = APP_VERSION_TWEAK_STRING;

    struct snapshot
    {
        bool utilityOn;
        std::array<bool, outletCount> outletOn;
        std::array<bool, outletCount> outletLoadConnected;
        std::array<sensors::hlw811x::measurements, outletCount> outletMeasurements;
        int rssiDbm;
        const char *latitude;
        const char *longitude;
        uint32_t upDaysMilli;
        uint32_t heartBeatDaysMilli;
        uint32_t batteryMillivolts;
    };

    bool utility_on(std::span<const sensors::hlw811x::measurements, outletCount> measurements);
    bool outlet_on(hardware::gpioCon &relay);
    bool outlet_load_connected(const sensors::hlw811x::measurements &measurement);
    bool average_frequency_centihz(std::span<const sensors::hlw811x::measurements, outletCount> measurements,
                                   int32_t &frequencyCentihz);
    bool frequency_bad(int32_t frequencyCentihz);
    bool power_factor_bad(const sensors::hlw811x::measurements &measurement);
    bool power_factor_restored(const sensors::hlw811x::measurements &measurement);
    uint32_t uptime_days_milli(int64_t bootTimeMs);
    int64_t heartbeat_interval_ms(uint32_t heartBeatDaysMilli);
    int64_t next_heartbeat_uptime_ms(int64_t bootTimeMs,
                                     uint32_t heartBeatDaysMilli,
                                     int64_t nowMs);

    snapshot make_snapshot(const cellular::sim7080::modemInformation &modemInformation,
                           std::span<hardware::gpioCon *, outletCount> relays,
                           std::span<const sensors::hlw811x::measurements, outletCount> measurements,
                           std::span<const bool, outletCount> monitoredLoadConnected,
                           std::span<const bool, outletCount> monitoredLoadStateValid,
                           int64_t bootTimeMs,
                           uint32_t heartBeatDaysMilli,
                           uint32_t batteryMillivolts);

    int format_status_message(const snapshot &status, char *buffer, std::size_t bufferSize);
    int format_alert_message(const snapshot &status,
                             std::string_view alert,
                             char *buffer,
                             std::size_t bufferSize);
    int format_outlet_report(const snapshot &status, char *buffer, std::size_t bufferSize);
    int format_single_outlet_report(const snapshot &status,
                                    std::size_t outletIndex,
                                    char *buffer,
                                    std::size_t bufferSize);
    int format_outlet_detail_report(const snapshot &status,
                                    std::size_t outletIndex,
                                    char *buffer,
                                    std::size_t bufferSize);
    int format_frequency_alert(std::string_view alert,
                               int32_t frequencyCentihz,
                               char *buffer,
                               std::size_t bufferSize);
    int format_power_factor_alert(const snapshot &status,
                                  std::string_view alert,
                                  std::size_t outletIndex,
                                  char *buffer,
                                  std::size_t bufferSize);

}
```

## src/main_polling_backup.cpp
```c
/*
 * Copyright (c) 2023, Meta
 *
 * SPDX-License-Identifier: Apache-2.0
 */

#include <iostream>
#include <cstring>
#include <zephyr/kernel.h>
#include "hardware/gpio_con.hpp"
#include "hardware/uart_con.hpp"
#include "sensors/hlw811x.hpp"

hardware::gpioCon utilityPwrLed(GPIO_DT_SPEC_GET(DT_ALIAS(utility_pwr_led), gpios), GPIO_OUTPUT_HIGH);
hardware::gpioCon cellularLed(GPIO_DT_SPEC_GET(DT_ALIAS(cellular_led), gpios), GPIO_OUTPUT_HIGH);
hardware::gpioCon relay4(GPIO_DT_SPEC_GET(DT_ALIAS(relay4), gpios), GPIO_OUTPUT_INACTIVE);
hardware::gpioCon gsmDtr(GPIO_DT_SPEC_GET(DT_ALIAS(gsm_dtr), gpios), GPIO_OUTPUT_INACTIVE);
hardware::gpioCon gsmPwrKey(GPIO_DT_SPEC_GET(DT_ALIAS(gsm_pwrkey), gpios), GPIO_OUTPUT_INACTIVE);
hardware::uartCon gsmUart(DEVICE_DT_GET(DT_ALIAS(gsm_uart)));
sensors::hlw811x energyMeters(
	DEVICE_DT_GET(DT_ALIAS(hlw_uart)),
	GPIO_DT_SPEC_GET(DT_ALIAS(energy_metering_mux_a), gpios),
	GPIO_DT_SPEC_GET(DT_ALIAS(energy_metering_mux_b), gpios),
	4);

static bool bufferContains(const uint8_t *buffer, int length, const char *needle)
{
	const int needleLength = static_cast<int>(std::strlen(needle));

	if (needleLength == 0 || length < needleLength) {
		return false;
	}

	for (int i = 0; i <= length - needleLength; ++i) {
		bool matched = true;

		for (int j = 0; j < needleLength; ++j) {
			if (buffer[i + j] != static_cast<uint8_t>(needle[j])) {
				matched = false;
				break;
			}
		}

		if (matched) {
			return true;
		}
	}

	return false;
}

static void printRx(const char *label, const uint8_t *buffer, int length)
{
	std::cout << label << " rx=" << length << " ";

	for (int i = 0; i < length; ++i) {
		const uint8_t c = buffer[i];

		if (c >= 0x20 && c <= 0x7e) {
			std::cout << static_cast<char>(c);
		} else if (c == '\r') {
			std::cout << "\\r";
		} else if (c == '\n') {
			std::cout << "\\n";
		} else {
			std::cout << "\\x" << std::hex << static_cast<int>(c) << std::dec;
		}
	}

	std::cout << std::endl;
}

static bool gsmCommand(const char *command, uint32_t timeoutMs, const char *expect = "OK")
{
	uint8_t rx[256] = {};

	gsmUart.flushRx();
	int tx = gsmUart.write(std::span<const uint8_t>(
		reinterpret_cast<const uint8_t *>(command), std::strlen(command)));
	k_msleep(50);
	int rxLength = gsmUart.read(std::span<uint8_t>(rx, sizeof(rx)), timeoutMs);

	std::cout << "GSM cmd tx=" << tx << " cmd=" << command;
	printRx("GSM", rx, rxLength);

	return bufferContains(rx, rxLength, expect);
}

static bool gsmTryAt()
{
	if (gsmCommand("AT\r\n", 8000)) {
		return true;
	}

	k_msleep(200);
	return gsmCommand("AT\r\n", 8000);
}

static bool gsmFindBaud(uint32_t &baudrate)
{
	const uint32_t baudrates[] = {115200, 9600, 57600, 38400, 19200};

	for (uint32_t baud : baudrates) {
		int ret = gsmUart.configureBaud(baud);
		std::cout << "GSM baud " << baud << " configure ret=" << ret << std::endl;

		if (ret == 0 && gsmTryAt()) {
			baudrate = baud;
			return true;
		}
	}

	return false;
}

static void gsmPowerPulse()
{
	gsmPwrKey.set(1);
	k_msleep(4000);
	gsmPwrKey.set(0);
	k_msleep(10000);
}

static void gsmBasicInit()
{
	uint32_t detectedBaud = 0;

	// if (!gsmFindBaud(detectedBaud)) {
	// 	std::cout << "GSM no AT response, pulsing PWRKEY" << std::endl;
	// 	gsmPowerPulse();
	// 	k_msleep(10000);

	// 	if (!gsmFindBaud(detectedBaud)) {
	// 		std::cout << "GSM still no AT response after PWRKEY" << std::endl;
	// 		return;
	// 	}
	// }

	gsmPowerPulse();

	std::cout << "GSM AT OK at baud " << detectedBaud << std::endl;
	gsmCommand("AT+IPR?\r\n", 5000);

	if (detectedBaud != 115200) {
		if (gsmCommand("AT+IPR=115200\r\n", 8000)) {
			k_msleep(200);
			gsmUart.configureBaud(115200);
			gsmTryAt();
		}
	}

	gsmCommand("ATE1\r\n", 8000);
}

int main(void)
{
	std::cout << "Hello, C++ world! " << CONFIG_BOARD << std::endl;

	utilityPwrLed.init();
	cellularLed.init();
	relay4.init();
	gsmDtr.init();
	gsmPwrKey.init();
	int gsmUartInit = gsmUart.init();
	std::cout << "GSM UART init: " << gsmUartInit << std::endl;
	// gsmBasicInit();
	gsmPowerPulse();
	int ret = energyMeters.init();
	std::cout << "HLW811x init: " << ret << std::endl;

	uint16_t sysStatus = 0;

	while (1) {
		// utilityPwrLed.toggle();
		// cellularLed.toggle();
		// relay4.toggle();
		hlw811x_error_t err = energyMeters.readSysStatus(4, sysStatus);
		std::cout << "HLW811x meter 1 sys status err=" << err
			  << " value=0x" << std::hex << sysStatus << std::dec << std::endl;

		constexpr uint8_t atCmd[] = {'A', 'T', '\r', '\n'};
		uint8_t gsmRx[128] = {};

		gsmUart.flushRx();
		int gsmTx = gsmUart.write(std::span<const uint8_t>(atCmd, sizeof(atCmd)));
		int gsmRxLen = gsmUart.read(std::span<uint8_t>(gsmRx, sizeof(gsmRx)), 10000);

		std::cout << "GSM AT tx=" << gsmTx << " rx=" << gsmRxLen << " ";
		for (int i = 0; i < gsmRxLen; ++i) {
			std::cout << static_cast<char>(gsmRx[i]);
		}
		std::cout << std::endl;

		k_msleep(3000);
	}
	return 0;
}
```
